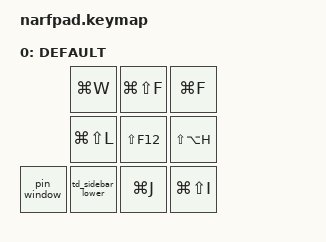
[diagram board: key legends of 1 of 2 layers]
#include <behaviors.dtsi>
#include <dt-bindings/zmk/keys.h>
#include <dt-bindings/zmk/bt.h>
#include <dt-bindings/zmk/outputs.h>

#define DEFAULT 0
#define LOWER   1

/ {
    behaviors {

        td_cmdl_cmdenter: td_cmdl_cmdenter {
            compatible = "zmk,behavior-tap-dance";
            #binding-cells = <0>;
            tapping-term-ms = <250>;
            bindings = <&kp LA(L) &kp LG(ENTER)>;
        };

        pin_window: pin_window {
            compatible = "zmk,behavior-macro";
            #binding-cells = <0>;
            /* Cursor: Pin = Cmd+R then Shift+Enter */
            bindings = <&kp LG(R) &kp LS(ENTER)>;
        };

        td_sidebar_lower: td_sidebar_lower {
            compatible = "zmk,behavior-tap-dance";
            #binding-cells = <0>;
            tapping-term-ms = <250>;
            bindings = <&kp LG(B) &tog LOWER>;
        };

        td_find: td_find {
            compatible = "zmk,behavior-tap-dance";
            #binding-cells = <0>;
            tapping-term-ms = <250>;
            bindings = <&kp LG(F) &kp LG(LS(F))>;
        };

        td_refs_hierarchy: td_refs_hierarchy {
            compatible = "zmk,behavior-tap-dance";
            #binding-cells = <0>;
            tapping-term-ms = <250>;
            /* VS Code (macOS): References = Shift+F12, Call Hierarchy = Shift+Option+H */
            bindings = <&kp  &kp >;
        };
    };

    keymap {
        compatible = "zmk,keymap";
        default_layer {
            label= "DEFAULT";
            bindings = <
                          &kp LG(W)           &kp LG(LS(F))    &kp LG(F)
                          &kp LG(LS(L))       &kp LS(F12)      &kp LS(LA(H))
            &pin_window   &td_sidebar_lower  &kp LG(J)       &kp LG(LS(I))
            >;
            /* VS Code/Cursor: cycle editors/tabs (Cmd+Opt+Right and Cmd+Opt+Left) */
            sensor-bindings = <&inc_dec_kp LG(LA(RIGHT)) LG(LA(LEFT))>;
        };
        lower_layer {
            label = "LOWER";
            bindings = <
                          &bt BT_PRV        &bt BT_CLR          &bt BT_NXT
                          &sys_reset        &none               &bootloader
             &none        &none             &none
            >;
            sensor-bindings = <&inc_dec_kp C_VOL_UP C_VOL_DN>;
        };
    };
};

